AUTOSAR XML (schema 4-2-2)
package /IOHWABSTR
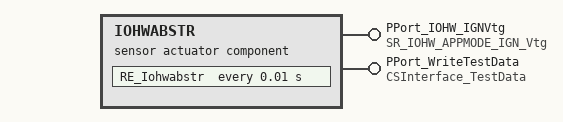
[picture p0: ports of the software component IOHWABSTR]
  sensor actuator sw component type IOHWABSTR
    provide port PPort_IOHW_IGNVtg: provided-interface=SR_IOHW_APPMODE_IGN_Vtg
    provide port PPort_WriteTestData: provided-interface=CSInterface_TestData
    behavior IB_IOHWABSTR: data-type-mapping=SR_IO_HW_APPMODEIF_MappingSet
      timing event TE_Iohwabstr_10ms: start-on-event=RE_Iohwabstr, period=0.01
      init event TE_Iohwabtr_Init: start-on-event=RE_Iohwabstr_Init
      operation invoked event OIE_WriteTestData: start-on-event=RE_WriteTestData, operation=PPort_WriteTestData.WriteTestData
      operation invoked event OIE_ReadTestData: start-on-event=RE_ReadTestData, operation=PPort_WriteTestData.ReadTestData
      4 x runnable:
        RE_Iohwabstr: symbol=Iohwabstr_Cyclic_10ms
          data-send-points:
            access DSP_IOHW_APPMODE_IGNVtg_VDP_0: accessed-variable=PPort_IOHW_IGNVtg.IOHW_APPMODE_IGNVtg_VDP
        RE_Iohwabstr_Init: symbol=Iohwabstr_Init
        RE_WriteTestData: symbol=Write_TestData
        RE_ReadTestData: symbol=Read_TestData
  compu method IOHW_CALIB_compu: raw=phys*10
package /IOHWABSTR/Sender_Reciever_IF
  app type ApplicationPrimitiveDataType_IO_HW_APPMODE_IF_SR: category=VALUE
  sender receiver interface SR_IOHW_APPMODE_IGN_Vtg
    data IOHW_APPMODE_IGNVtg_VDP: sw-calibration-access=READ-ONLY, type=ApplicationPrimitiveDataType_IO_HW_APPMODE_IF_SR
  data type mapping set SR_IO_HW_APPMODEIF_MappingSet: data-type-map{application-data-type=ApplicationPrimitiveDataType_IO_HW_APPMODE_IF_SR, implementation-data-type=uint32}
